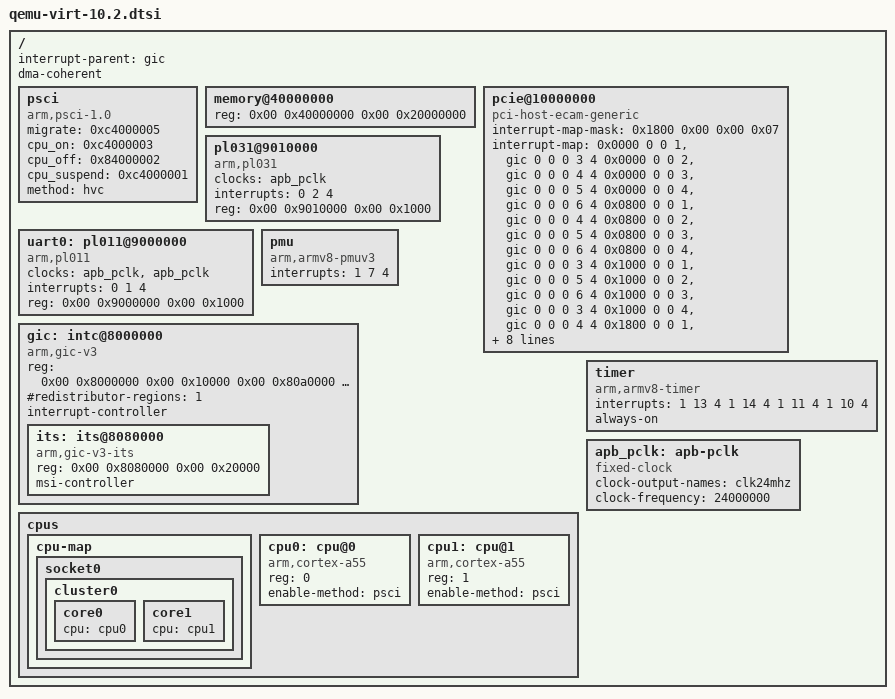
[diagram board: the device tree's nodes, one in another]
// SPDX-License-Identifier: GPL-2.0-or-later
/*
 * QEMU's arm64 "virt-10.2" machine (gic-version=3, -cpu cortex-a55 -smp 2), as its own
 * dumpdtb prints it, less the devices a virtual ONU does not use (virtio-mmio, pflash,
 * fw-cfg, the platform bus, the PL061 power key). A versioned machine keeps these
 * addresses fixed; QEMU rewrites /memory from -m when it loads this tree.
 */

/ {
	interrupt-parent = <&gic>;
	dma-coherent;
	#size-cells = <2>;
	#address-cells = <2>;

	psci {
		migrate = <0xc4000005>;
		cpu_on = <0xc4000003>;
		cpu_off = <0x84000002>;
		cpu_suspend = <0xc4000001>;
		method = "hvc";
		compatible = "arm,psci-1.0", "arm,psci-0.2", "arm,psci";
	};

	memory@40000000 {
		reg = <0x00 0x40000000 0x00 0x20000000>;
		device_type = "memory";
	};

	pcie@10000000 {
		interrupt-map-mask = <0x1800 0x00 0x00 0x07>;
		interrupt-map = <
			0x0000 0 0 1 &gic 0 0 0 3 4  0x0000 0 0 2 &gic 0 0 0 4 4
			0x0000 0 0 3 &gic 0 0 0 5 4  0x0000 0 0 4 &gic 0 0 0 6 4
			0x0800 0 0 1 &gic 0 0 0 4 4  0x0800 0 0 2 &gic 0 0 0 5 4
			0x0800 0 0 3 &gic 0 0 0 6 4  0x0800 0 0 4 &gic 0 0 0 3 4
			0x1000 0 0 1 &gic 0 0 0 5 4  0x1000 0 0 2 &gic 0 0 0 6 4
			0x1000 0 0 3 &gic 0 0 0 3 4  0x1000 0 0 4 &gic 0 0 0 4 4
			0x1800 0 0 1 &gic 0 0 0 6 4  0x1800 0 0 2 &gic 0 0 0 3 4
			0x1800 0 0 3 &gic 0 0 0 4 4  0x1800 0 0 4 &gic 0 0 0 5 4>;
		#interrupt-cells = <1>;
		ranges = <0x1000000 0x00 0x00 0x00 0x3eff0000 0x00 0x10000
			  0x2000000 0x00 0x10000000 0x00 0x10000000 0x00 0x2eff0000
			  0x3000000 0x80 0x00 0x80 0x00 0x80 0x00>;
		reg = <0x40 0x10000000 0x00 0x10000000>;
		msi-map = <0x00 &its 0x00 0x10000>;
		dma-coherent;
		bus-range = <0x00 0xff>;
		linux,pci-domain = <0>;
		#size-cells = <2>;
		#address-cells = <3>;
		device_type = "pci";
		compatible = "pci-host-ecam-generic";
	};

	pl031@9010000 {
		clock-names = "apb_pclk";
		clocks = <&apb_pclk>;
		interrupts = <0 2 4>;
		reg = <0x00 0x9010000 0x00 0x1000>;
		compatible = "arm,pl031", "arm,primecell";
	};

	uart0: pl011@9000000 {
		clock-names = "uartclk", "apb_pclk";
		clocks = <&apb_pclk &apb_pclk>;
		interrupts = <0 1 4>;
		reg = <0x00 0x9000000 0x00 0x1000>;
		compatible = "arm,pl011", "arm,primecell";
	};

	pmu {
		interrupts = <1 7 4>;
		compatible = "arm,armv8-pmuv3";
	};

	gic: intc@8000000 {
		reg = <0x00 0x8000000 0x00 0x10000 0x00 0x80a0000 0x00 0xf60000>;
		#redistributor-regions = <1>;
		compatible = "arm,gic-v3";
		ranges;
		#size-cells = <2>;
		#address-cells = <2>;
		interrupt-controller;
		#interrupt-cells = <3>;

		its: its@8080000 {
			reg = <0x00 0x8080000 0x00 0x20000>;
			#msi-cells = <1>;
			msi-controller;
			compatible = "arm,gic-v3-its";
		};
	};

	cpus {
		#size-cells = <0>;
		#address-cells = <1>;

		cpu-map {
			socket0 {
				cluster0 {
					core0 {
						cpu = <&cpu0>;
					};
					core1 {
						cpu = <&cpu1>;
					};
				};
			};
		};

		cpu0: cpu@0 {
			reg = <0>;
			enable-method = "psci";
			compatible = "arm,cortex-a55";
			device_type = "cpu";
		};

		cpu1: cpu@1 {
			reg = <1>;
			enable-method = "psci";
			compatible = "arm,cortex-a55";
			device_type = "cpu";
		};
	};

	timer {
		interrupts = <1 13 4 1 14 4 1 11 4 1 10 4>;
		always-on;
		compatible = "arm,armv8-timer", "arm,armv7-timer";
	};

	apb_pclk: apb-pclk {
		clock-output-names = "clk24mhz";
		clock-frequency = <24000000>;
		#clock-cells = <0>;
		compatible = "fixed-clock";
	};
};
